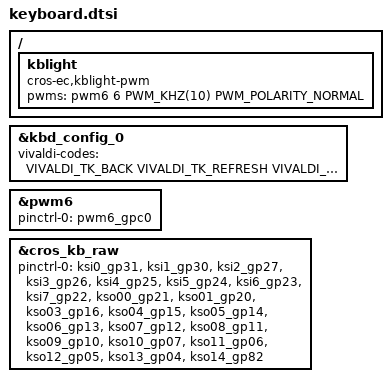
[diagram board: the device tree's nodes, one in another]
/* Copyright 2022 The ChromiumOS Authors
 * Use of this source code is governed by a BSD-style license that can be
 * found in the LICENSE file.
 */

/ {
	kblight {
		compatible = "cros-ec,kblight-pwm";
		pwms = <&pwm6 6 PWM_KHZ(10) PWM_POLARITY_NORMAL>;
	};
};

&kbd_config_0 {
	vivaldi-codes = <
		VIVALDI_TK_BACK             /* T1 */
		VIVALDI_TK_REFRESH          /* T2 */
		VIVALDI_TK_FULLSCREEN       /* T3 */
		VIVALDI_TK_OVERVIEW         /* T4 */
		VIVALDI_TK_SNAPSHOT         /* T5 */
		VIVALDI_TK_BRIGHTNESS_DOWN  /* T6 */
		VIVALDI_TK_BRIGHTNESS_UP    /* T7 */
		VIVALDI_TK_VOL_MUTE         /* T8 */
		VIVALDI_TK_VOL_DOWN         /* T9 */
		VIVALDI_TK_VOL_UP           /* T10 */
	>;
};

&pwm6 {
	status = "okay";
	pinctrl-0 = <&pwm6_gpc0>;
	pinctrl-names = "default";
};

&cros_kb_raw {
	status = "okay";
	/* No KSO2 (it's inverted and implemented by GPIO) */
	pinctrl-0 = <
		&ksi0_gp31
		&ksi1_gp30
		&ksi2_gp27
		&ksi3_gp26
		&ksi4_gp25
		&ksi5_gp24
		&ksi6_gp23
		&ksi7_gp22
		&kso00_gp21
		&kso01_gp20
		&kso03_gp16
		&kso04_gp15
		&kso05_gp14
		&kso06_gp13
		&kso07_gp12
		&kso08_gp11
		&kso09_gp10
		&kso10_gp07
		&kso11_gp06
		&kso12_gp05
		&kso13_gp04
		&kso14_gp82
	>;
	pinctrl-names = "default";
};
